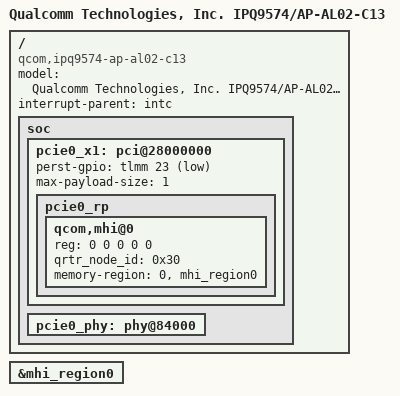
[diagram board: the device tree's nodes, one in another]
// SPDX-License-Identifier: (GPL-2.0+ OR BSD-3-Clause)
/*
 * IPQ9574 AL02-C13 board device tree source
 *
 * Copyright (c) 2020-2021 The Linux Foundation. All rights reserved.
 * Copyright (c) 2021-2022 Qualcomm Innovation Center, Inc. All rights reserved.
 */

/dts-v1/;

#include "ipq9574-al02-c4.dts"

/ {
        #address-cells = <0x2>;
        #size-cells = <0x2>;
        model = "Qualcomm Technologies, Inc. IPQ9574/AP-AL02-C13";
        compatible = "qcom,ipq9574-ap-al02-c13", "qcom,ipq9574-al02", "qcom,ipq9574";
        interrupt-parent = <&intc>;
	soc {
		pcie0_x1: pci@28000000 {
			perst-gpio = <&tlmm 23 1>;
			max-payload-size = <1>; // 1-256 TLP bytes for WKK
			status = "ok";
			pcie0_rp {
				qcom,mhi@0 {
					reg = <0 0 0 0 0>;
					qrtr_node_id = <0x30>;
					memory-region = <0>,<&mhi_region0>;
				};
			};
		};

		pcie0_phy: phy@84000 {
			status ="ok";
		};
	};
};

&mhi_region0 {
	status = "ok";
};
